# CM4 register map
CPU: CM4 r0p1, selectable endian, MPU, FPU, 3 interrupt priority bits
Registers are 32-bit, read-write, reset 0x0 unless marked. A register's access mark holds for its fields unless they carry their own. Offsets are from the block's base; [hi:lo] are bit positions; {n}, {i} and the like mark numbered series.

## DWT — Data Watchpoint and Trace
Base 0xE0001000
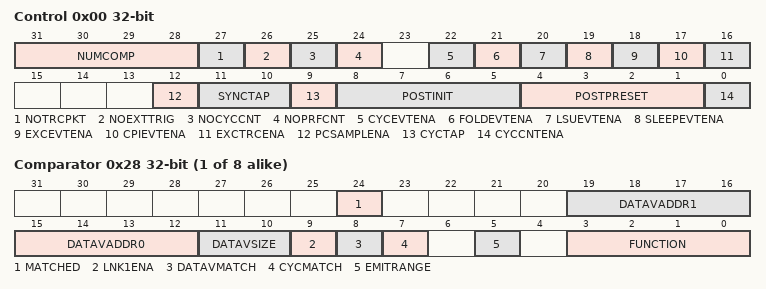
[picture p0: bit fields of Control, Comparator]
0x00 Control register — Provides configuration and status information for the DWT unit, and used to control features of the unit
  [31:28] NUMCOMP — Number of comparators implemented
  [27] NOTRCPKT — Shows whether the implementation supports trace sampling and exception tracing
    0=Trace sampling and exception tracing supported; 1=Trace sampling and exception tracing not supported
  [26] NOEXTTRIG — Shows whether the implementation includes external match signals, CMPMATCH[N]
    0=CMPMATCH[N] supported; 1=CMPMATCH[N] not supported
  [25] NOCYCCNT — Shows whether the implementation supports a cycle counter
    0=Cycle counter supported; 1=Cycle counter not supported
  [24] NOPRFCNT — Shows whether the implementation supports the profiling counters
    0=Supported; 1=Not supported
  [22] CYCEVTENA — Enables POSTCNT underflow Event counter packets generation
    0=No POSTCNT underflow packets generated; 1=POSTCNT underflow packets generated, if PCSAMPLENA set to 0
  [21] FOLDEVTENA — Enables generation of the Folded-instruction counter overflow event
    0=Disabled; 1=Enabled
  [20] LSUEVTENA — Enables generation of the LSU counter overflow event
    0=Disabled; 1=Enabled
  [19] SLEEPEVTENA — Enables generation of the Sleep counter overflow event
    0=Disabled; 1=Enabled
  [18] EXCEVTENA — Enables generation of the Exception overhead counter overflow event
    0=Disabled; 1=Enabled
  [17] CPIEVTENA — Enables generation of the CPI counter overflow event
    0=Disabled; 1=Enabled
  [16] EXCTRCENA — Enables generation of exception trace
    0=Disabled; 1=Enabled
  [12] PCSAMPLENA — Enables use of POSTCNT counter as a timer for Periodic PC sample packet generation
    0=No Periodic PC sample packets generated; 1=Periodic PC sample packets generated
  [11:10] SYNCTAP — Selects the position of the synchronization packet counter tap on the CYCCNT counter
    0=Disabled. No Synchronization packets; 10=Synchronization counter tap at CYCCNT[26]; 11=Synchronization counter tap at CYCCNT[28]
  [9] CYCTAP — Selects the position of the POSTCNT tap on the CYCCNT counter
    0=POSTCNT tap at CYCCNT[6]; 1=POSTCNT tap at CYCCNT[10]
  [8:5] POSTINIT — Initial value for the POSTCNT counter
  [4:1] POSTPRESET — Reload value for the POSTCNT counter
  [0] CYCCNTENA — Enables CYCCNT
    0=Disabled; 1=Enabled
0x04 Cycle Count register — Shows or sets the value of the processor cycle counter, CYCCNT
  [31:0] CYCCNT — Incrementing cycle counter value
0x08 CPI Count register — Counts additional cycles required to execute multi-cycle instructions and instruction fetch stalls
  [7:0] CPICNT — Base instruction overhead counter
0x0C Exception Overhead Count register — Counts the total cycles spent in exception processing
  [7:0] EXCCNT — The exception overhead counter
0x10 Sleep Count register — Counts the total number of cycles that the processor is sleeping
  [7:0] SLEEPCNT — Sleep counter
0x14 LSU Count register — Increments on the additional cycles required to execute all load or store instructions
  [7:0] LSUCNT — Load-store overhead counter
0x18 Folded-instruction Count register — Increments on each instruction that takes 0 cycles
  [7:0] FOLDCNT — Folded instruction counter
0x1C Program Counter Sample Register ro — Samples the current value of the program counter
  [31:0] EIASAMPLE — Executed Instruction Address sample value
{0x20+4i} Comparator register[{i}] (i=0..7) — Provides a reference value for use by comparator n
  [31:0] COMP — Reference value for comparison
{0x24+4i} Comparator Mask Register {i} (i=0..7) — Provides the size of the ignore mask applied to the access address for address range matching by comparator n
  [4:0] MASK — The size of the ignore mask, 0-31 bits, applied to address range matching
{0x28+4i} Comparator Function Register {i} (i=0..7) — Controls the operation of comparator n
  [24] MATCHED — Comparator match
    0=No match; 1=Match
  [19:16] DATAVADDR1 — When the DATAVMATCH and LNK1ENA bits are both 1, this field can hold the comparator number of a second comparator to use for linked address comparison
  [15:12] DATAVADDR0 — When the DATAVMATCH bit is set to 1 this field can hold the comparator number of a comparator to use for linked address comparison
  [11:10] DATAVSIZE — For data value matching, specifies the size of the required data comparison
    0=Byte; 1=Halfword; 10=Word
  [9] LNK1ENA — Indicates whether the implementation supports use of a second linked comparator
    0=Second linked comparator not supported; 1=Second linked comparator supported
  [8] DATAVMATCH — Enables data value comparison, if supported
    0=Perform address comparison; 1=Perform data value comparison
  [7] CYCMATCH — DWT_FUNCTION0 only
    0=No comparison is performed; 1=Compare DWT_COMP0 with the cycle counter, DWT_CYCCNT
  [5] EMITRANGE — If the implementation supports trace sampling, enables generation of Data trace address packets, that hold Daddr[15
    0=Data trace address packets disabled; 1=Enable Data trace address packet generation
  [3:0] FUNCTION — Selects action taken on comparator match
    0== Disabled or LinkAddr()
